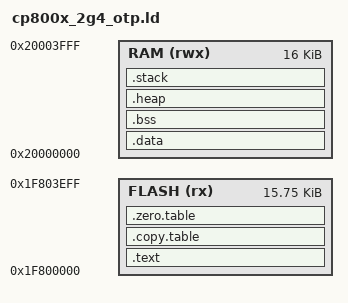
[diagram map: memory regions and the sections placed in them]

__ROM_BASE = 0x1F800000;
__ROM_SIZE = 0x00003F00;

__RAM_BASE = 0x20000000;
__RAM_SIZE = 0x00004000;

__STACK_SIZE = 0x00000300;
__HEAP_SIZE  = 0x00000000;

MEMORY
{
    FLASH (rx)  : ORIGIN = __ROM_BASE, LENGTH = __ROM_SIZE
    RAM   (rwx) : ORIGIN = __RAM_BASE, LENGTH = __RAM_SIZE
}

/* Linker script to place sections and symbol values. Should be used together
 * with other linker script that defines memory regions FLASH and RAM.
 * It references following symbols, which must be defined in code:
 *   reset_Handler : Entry of reset handler
 *
 * It defines following symbols, which code can use without definition:
 *   __exidx_start
 *   __exidx_end
 *   __copy_table_start__
 *   __copy_table_end__
 *   __zero_table_start__
 *   __zero_table_end__
 *   __etext
 *   __data_start__
 *   __preinit_array_start
 *   __preinit_array_end
 *   __init_array_start
 *   __init_array_end
 *   __fini_array_start
 *   __fini_array_end
 *   __data_end__
 *   __bss_start__
 *   __bss_end__
 *   __end__
 *   end
 *   __HeapLimit
 *   __StackLimit
 *   __StackTop
 *   __stack
 */

ENTRY(reset_handler)

SECTIONS
{
  .text :
  {
    /* KEEP(*(.text.init)) */
    *crt0*.o(.text .text.*)
    *(EXCLUDE_FILE(*t1001_flash.o) .text*)
    /* *(.text*) */

    KEEP(*(.init))
    KEEP(*(.fini))

    /* .ctors */
    *crtbegin.o(.ctors)
    *crtbegin?.o(.ctors)
    *(EXCLUDE_FILE(*crtend?.o *crtend.o) .ctors)
    *(SORT(.ctors.*))
    *(.ctors)

    /* .dtors */
    *crtbegin.o(.dtors)
    *crtbegin?.o(.dtors)
    *(EXCLUDE_FILE(*crtend?.o *crtend.o) .dtors)
    *(SORT(.dtors.*))
    *(.dtors)

    *(.rodata*)

    KEEP(*(.eh_frame*))
  } > FLASH

  /*
   * SG veneers:
   * All SG veneers are placed in the special output section .gnu.sgstubs. Its start address
   * must be set, either with the command line option --section-start or in a linker script,
   * to indicate where to place these veneers in memory.
   */

  __exidx_end = .;

  .copy.table :
  {
    . = ALIGN(4);
    __copy_table_start__ = .;

    LONG (__etext)
    LONG (__data_start__)
    LONG ((__data_end__ - __data_start__) / 4)
/*
    LONG (__ram_code)
    LONG (__rc_start)
    LONG ((__rc_end - __rc_start) / 4)
*/
    __copy_table_end__ = .;
  } > FLASH

  .zero.table :
  {
    . = ALIGN(4);
    __zero_table_start__ = .;
    /* Add each additional bss section here */
    LONG (__bss_start__)
    LONG ((__bss_end__ - __bss_start__) / 4)

    __zero_table_end__ = .;
  } > FLASH

  /**
   * Location counter can end up 2byte aligned with narrow Thumb code but
   * __etext is assumed by startup code to be the LMA of a section in RAM
   * which must be 4byte aligned
   */
  __etext = ALIGN (4);
  /* __ram_code = __etext + (__data_end__ - __data_start__); */

  .data : AT (__etext)
  {
    __data_start__ = .;
    *(.data.__VECTOR_TABLE)
    *(vtable)
    *(.data)
    *(.data.*)

    . = ALIGN(4);
    /* preinit data */
    PROVIDE_HIDDEN (__preinit_array_start = .);
    KEEP(*(.preinit_array))
    PROVIDE_HIDDEN (__preinit_array_end = .);

    . = ALIGN(4);
    /* init data */
    PROVIDE_HIDDEN (__init_array_start = .);
    KEEP(*(SORT(.init_array.*)))
    KEEP(*(.init_array))
    PROVIDE_HIDDEN (__init_array_end = .);

    . = ALIGN(4);
    /* finit data */
    PROVIDE_HIDDEN (__fini_array_start = .);
    KEEP(*(SORT(.fini_array.*)))
    KEEP(*(.fini_array))
    PROVIDE_HIDDEN (__fini_array_end = .);

    KEEP(*(.jcr*))

    *(.ram_code_section .ram_code_section.*)
    *(.context_switch .context_switch.*)

    /* must align 4 */
    . = ALIGN(4);
    /* All data end */
    __data_end__ = .;

  } > RAM
/*
  .ram_code : AT (__ram_code)
  {
    . = ALIGN(4);
    __rc_start = .;
    *(.flash_ram_code .flash_ram_code.*)
    . = ALIGN(4);
    __rc_end = .;
  } > RAM
*/
  /*
   * Secondary data section, optional
   *
   * Remember to add each additional data section
   * to the .copy.table above to asure proper
   * initialization during startup.
   */

  .bss :
  {
    . = ALIGN(4);
    __bss_start__ = .;
    *(.bss)
    *(.bss.*)
    *(COMMON)
    . = ALIGN(4);
    __bss_end__ = .;
  } > RAM AT > RAM

  /*
   * Secondary bss section, optional
   *
   * Remember to add each additional bss section
   * to the .zero.table above to asure proper
   * initialization during startup.
   */

  .heap (COPY) :
  {
    . = ALIGN(8);
    __end__ = .;
    PROVIDE(end = .);
    . = . + __HEAP_SIZE;
    . = ALIGN(8);
    __HeapLimit = .;
  } > RAM

  .stack (ORIGIN(RAM) + LENGTH(RAM) - __STACK_SIZE) (COPY) :
  {
    . = ALIGN(8);
    __StackLimit = .;
    . = . + __STACK_SIZE;
    . = ALIGN(8);
    __StackTop = .;
  } > RAM
  PROVIDE(__stack = __StackTop);

  /* Check if data + heap + stack exceeds RAM limit */
  ASSERT(__StackLimit >= __HeapLimit, "region RAM overflowed with stack")  
}
